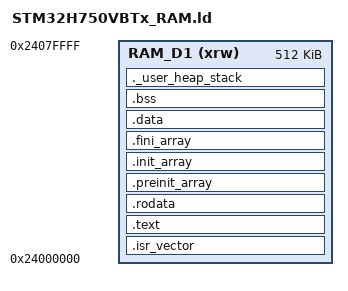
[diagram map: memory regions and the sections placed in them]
/* Entry Point */
ENTRY(Reset_Handler)

/* Specify the memory areas */
MEMORY
{
  RAM_D1 (xrw)      : ORIGIN = 0x24000000, LENGTH = 512K
}

/* Highest address of the user mode stack */
_estack = ORIGIN(RAM_D1) + LENGTH(RAM_D1);    /* end of RAM */

/* Generate a link error if heap and stack don't fit into RAM */
_Min_Heap_Size = 0x200;      /* required amount of heap  */
_Min_Stack_Size = 0x400; /* required amount of stack */



/* Define output sections */
SECTIONS
{
  /* The startup code goes first into FLASH */
  .isr_vector :
  {
    . = ALIGN(4);
    KEEP(*(.isr_vector)) /* Startup code */
    . = ALIGN(4);
  } >RAM_D1

  /* The program code and other data goes into FLASH */
  .text :
  {
    . = ALIGN(4);
    *(.text)           /* .text sections (code) */
    *(.text*)          /* .text* sections (code) */
    . = ALIGN(4);
  } >RAM_D1

  /* Constant data goes into FLASH */
  .rodata :
  {
    . = ALIGN(4);
    *(.rodata)         /* .rodata sections (constants, strings, etc.) */
    *(.rodata*)        /* .rodata* sections (constants, strings, etc.) */
    . = ALIGN(4);
  } >RAM_D1
  .preinit_array     :
  {
    PROVIDE_HIDDEN (__preinit_array_start = .);
    KEEP (*(.preinit_array*))
    PROVIDE_HIDDEN (__preinit_array_end = .);
  } >RAM_D1
  .init_array :
  {
    PROVIDE_HIDDEN (__init_array_start = .);
    KEEP (*(SORT(.init_array.*)))
    KEEP (*(.init_array*))
    PROVIDE_HIDDEN (__init_array_end = .);
  } >RAM_D1
  .fini_array :
  {
    PROVIDE_HIDDEN (__fini_array_start = .);
    KEEP (*(SORT(.fini_array.*)))
    KEEP (*(.fini_array*))
    PROVIDE_HIDDEN (__fini_array_end = .);
  } >RAM_D1

  /* Initialized data sections goes into RAM, load LMA copy after code */
  .data : 
  {
    . = ALIGN(4);
    *(.data)           /* .data sections */
    *(.data*)          /* .data* sections */
  } >RAM_D1

  /* Uninitialized data section */
  . = ALIGN(4);
  .bss :
  {
    _sbss = .;         /* define a global symbol at bss start */
    *(.bss)
    *(.bss*)
    *(COMMON)
    . = ALIGN(4);
    _ebss = .;         /* define a global symbol at bss end */
  } >RAM_D1

  /* User_heap_stack section, used to check that there is enough RAM left */
  ._user_heap_stack :
  {
    . = ALIGN(8);
    PROVIDE ( end = . );
    PROVIDE ( _end = . );
    . = . + _Min_Heap_Size;
    . = . + _Min_Stack_Size;
    . = ALIGN(8);
  } >RAM_D1
  /* Remove information from the standard libraries */
  /DISCARD/ :
  {
    libc.a ( * )
    libm.a ( * )
    libgcc.a ( * )
  }
}


